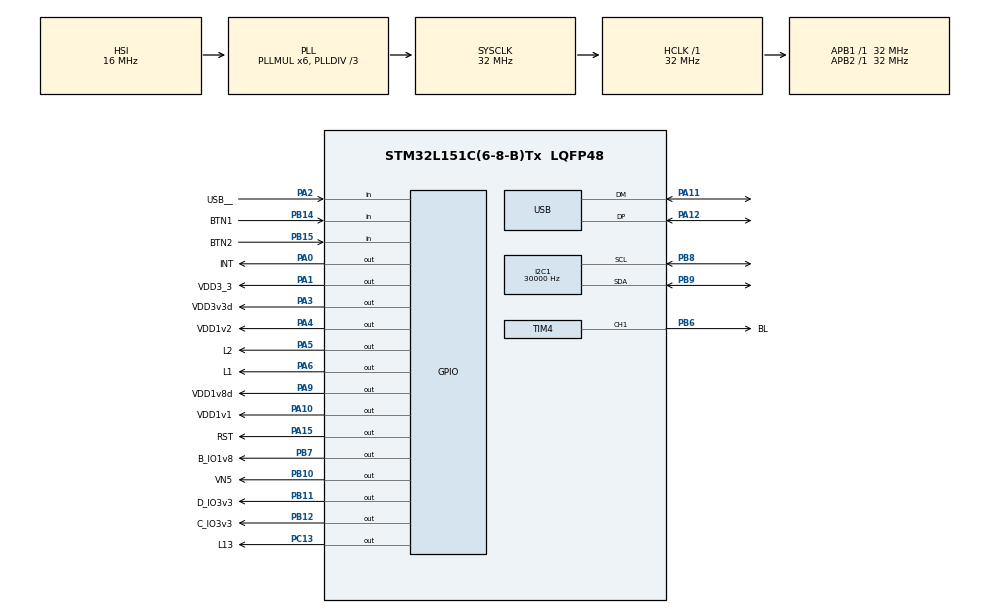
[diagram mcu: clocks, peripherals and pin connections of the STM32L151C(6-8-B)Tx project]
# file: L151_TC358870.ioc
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ADC.Channel-10\#ChannelRegularConversion=ADC_CHANNEL_TEMPSENSOR
ADC.Channel-9\#ChannelRegularConversion=ADC_CHANNEL_VREFINT
ADC.NbrOfConversion=2
ADC.NbrOfConversionFlag=1
ADC.Rank-10\#ChannelRegularConversion=2
ADC.Rank-9\#ChannelRegularConversion=1
ADC.SamplingTime-10\#ChannelRegularConversion=ADC_SAMPLETIME_384CYCLES
ADC.SamplingTime-9\#ChannelRegularConversion=ADC_SAMPLETIME_384CYCLES
I2C1.ClockSpeed=30000
I2C1.I2C_Mode=I2C_Standard
Mcu.Family=STM32L1
Mcu.Name=STM32L151C(6-8-B)Tx
Mcu.Package=LQFP48
NVIC.PriorityGroup=NVIC_PRIORITYGROUP_4
NVIC.USB_LP_IRQn=true\:0\:0\:false\:false\:true\:false\:true\:true
PA0-WKUP1.GPIO_Label=INT
PA0-WKUP1.GPIO_ModeDefaultOutputPP=GPIO_MODE_OUTPUT_OD
PA0-WKUP1.GPIO_PuPd=GPIO_PULLUP
PA0-WKUP1.GPIO_Speed=GPIO_SPEED_FREQ_VERY_HIGH
PA0-WKUP1.PinState=GPIO_PIN_SET
PA0-WKUP1.Signal=GPIO_Output
PA1.GPIO_Label=VDD3_3
PA1.GPIO_Speed=GPIO_SPEED_FREQ_VERY_HIGH
PA1.PinState=GPIO_PIN_RESET
PA1.Signal=GPIO_Output
PA10.GPIO_Label=VDD1v1
PA10.GPIO_Speed=GPIO_SPEED_FREQ_VERY_HIGH
PA10.PinState=GPIO_PIN_RESET
PA10.Signal=GPIO_Output
PA11.Mode=Device
PA11.Signal=USB_DM
PA12.Mode=Device
PA12.Signal=USB_DP
PA13.Mode=Serial_Wire
PA13.Signal=SYS_JTMS-SWDIO
PA14.Mode=Serial_Wire
PA14.Signal=SYS_JTCK-SWCLK
PA15.GPIO_Label=RST
PA15.GPIO_Speed=GPIO_SPEED_FREQ_VERY_HIGH
PA15.PinState=GPIO_PIN_RESET
PA15.Signal=GPIO_Output
PA2.GPIO_Label=USB__
PA2.Signal=GPIO_Input
PA3.GPIO_Label=VDD3v3d
PA3.GPIO_Speed=GPIO_SPEED_FREQ_VERY_HIGH
PA3.PinState=GPIO_PIN_SET
PA3.Signal=GPIO_Output
PA4.GPIO_Label=VDD1v2
PA4.GPIO_Speed=GPIO_SPEED_FREQ_VERY_HIGH
PA4.PinState=GPIO_PIN_RESET
PA4.Signal=GPIO_Output
PA5.GPIO_Label=L2
PA5.GPIO_Speed=GPIO_SPEED_FREQ_VERY_HIGH
PA5.Signal=GPIO_Output
PA6.GPIO_Label=L1
PA6.GPIO_Speed=GPIO_SPEED_FREQ_VERY_HIGH
PA6.Signal=GPIO_Output
PA9.GPIO_Label=VDD1v8d
PA9.GPIO_Speed=GPIO_SPEED_FREQ_VERY_HIGH
PA9.Signal=GPIO_Output
PB10.GPIO_Label=VN5
PB10.GPIO_Speed=GPIO_SPEED_FREQ_VERY_HIGH
PB10.PinState=GPIO_PIN_RESET
PB10.Signal=GPIO_Output
PB11.GPIO_Label=D_IO3v3
PB11.GPIO_Speed=GPIO_SPEED_FREQ_VERY_HIGH
PB11.PinState=GPIO_PIN_RESET
PB11.Signal=GPIO_Output
PB12.GPIO_Label=C_IO3v3
PB12.GPIO_Speed=GPIO_SPEED_FREQ_VERY_HIGH
PB12.PinState=GPIO_PIN_RESET
PB12.Signal=GPIO_Output
PB14.GPIO_Label=BTN1
PB14.Signal=GPIO_Input
PB15.GPIO_Label=BTN2
PB15.Signal=GPIO_Input
PB6.GPIO_Label=BL
PB6.Signal=S_TIM4_CH1
PB7.GPIO_Label=B_IO1v8
PB7.GPIO_Speed=GPIO_SPEED_FREQ_VERY_HIGH
PB7.PinState=GPIO_PIN_RESET
PB7.Signal=GPIO_Output
PB8.Mode=I2C
PB8.Signal=I2C1_SCL
PB9.Mode=I2C
PB9.Signal=I2C1_SDA
PC13-WKUP2.GPIO_Label=L13
PC13-WKUP2.Signal=GPIO_Output
ProjectManager.HeapSize=0x200
ProjectManager.StackSize=0x400
ProjectManager.TargetToolchain=STM32CubeIDE
RCC.48MHZClocksFreq_Value=48000000
RCC.AHBFreq_Value=32000000
RCC.APB1Freq_Value=32000000
RCC.APB1TimFreq_Value=32000000
RCC.APB2Freq_Value=32000000
RCC.APB2TimFreq_Value=32000000
RCC.HCLKFreq_Value=32000000
RCC.HSE_VALUE=12000000
RCC.HSI_VALUE=16000000
RCC.LSE_VALUE=32768
RCC.MSI_VALUE=2097000
RCC.PLLDIV=RCC_PLL_DIV3
RCC.PLLMUL=RCC_PLL_MUL6
RCC.PLLSource=RCC_PLLSOURCE_HSI
RCC.PLLSourceVirtualString=RCC_PLLSOURCE_HSI
RCC.SYSCLKFreq_VALUE=32000000
RCC.SYSCLKSource=RCC_SYSCLKSOURCE_PLLCLK
RCC.VCOOutputFreq_Value=96000000
SH.S_TIM4_CH1.0=TIM4_CH1,PWM Generation1 CH1
TIM4.Channel-PWM\ Generation1\ CH1=TIM_CHANNEL_1
TIM4.Period=100
TIM4.Prescaler=3
TIM4.Pulse-PWM\ Generation1\ CH1=50
USB_DEVICE.CLASS_NAME_FS=CDC
USB_DEVICE.VirtualMode=Cdc
USB_DEVICE.VirtualModeFS=Cdc_FS
VP_ADC_TempSens_Input.Mode=IN-TempSens
VP_ADC_Vref_Input.Mode=IN-Vrefint
VP_USB_DEVICE_VS_USB_DEVICE_CDC_FS.Mode=CDC_FS
board=custom

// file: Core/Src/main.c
/* USER CODE BEGIN Header */
/**
  ******************************************************************************
  * @file           : main.c
  * @brief          : Main program body
  ******************************************************************************
  * @attention
  *
  * Copyright (c) 2024 STMicroelectronics.
  * All rights reserved.
  *
  * This software is licensed under terms that can be found in the LICENSE file
  * in the root directory of this software component.
  * If no LICENSE file comes with this software, it is provided AS-IS.
  *
  ******************************************************************************
  */
/* USER CODE END Header */
#include "main.h"
#include "adc.h"
#include "i2c.h"
#include "tim.h"
#include "usb_device.h"
#include "gpio.h"

/* USER CODE BEGIN Includes */
#include "kernel.h"
/* USER CODE END Includes */

void SystemClock_Config(void);

int main(void)
{

  /* MCU Configuration--------------------------------------------------------*/

  /* Reset of all peripherals, Initializes the Flash interface and the Systick. */
  HAL_Init();

  /* Configure the system clock */
  SystemClock_Config();

  /* Initialize all configured peripherals */
  MX_GPIO_Init();
  MX_ADC_Init();
//  MX_USB_DEVICE_Init();
  MX_I2C1_Init();
  MX_TIM4_Init();

  /* Infinite loop */
  /* USER CODE BEGIN WHILE */
  while (1)
  {
	  kernel_main();
    /* USER CODE END WHILE */

  }
}

void SystemClock_Config(void)
{
  RCC_OscInitTypeDef RCC_OscInitStruct = {0};
  RCC_ClkInitTypeDef RCC_ClkInitStruct = {0};

  /** Configure the main internal regulator output voltage
  */
  __HAL_PWR_VOLTAGESCALING_CONFIG(PWR_REGULATOR_VOLTAGE_SCALE1);

  /** Initializes the RCC Oscillators according to the specified parameters
  * in the RCC_OscInitTypeDef structure.
  */
  RCC_OscInitStruct.OscillatorType = RCC_OSCILLATORTYPE_HSI;
  RCC_OscInitStruct.HSIState = RCC_HSI_ON;
  RCC_OscInitStruct.HSICalibrationValue = RCC_HSICALIBRATION_DEFAULT;
  RCC_OscInitStruct.PLL.PLLState = RCC_PLL_ON;
  RCC_OscInitStruct.PLL.PLLSource = RCC_PLLSOURCE_HSI;
  RCC_OscInitStruct.PLL.PLLMUL = RCC_PLL_MUL6;
  RCC_OscInitStruct.PLL.PLLDIV = RCC_PLL_DIV3;
  if (HAL_RCC_OscConfig(&RCC_OscInitStruct) != HAL_OK)
  {
    Error_Handler();
  }

  /** Initializes the CPU, AHB and APB buses clocks
  */
  RCC_ClkInitStruct.ClockType = RCC_CLOCKTYPE_HCLK|RCC_CLOCKTYPE_SYSCLK
                              |RCC_CLOCKTYPE_PCLK1|RCC_CLOCKTYPE_PCLK2;
  RCC_ClkInitStruct.SYSCLKSource = RCC_SYSCLKSOURCE_PLLCLK;
  RCC_ClkInitStruct.AHBCLKDivider = RCC_SYSCLK_DIV1;
  RCC_ClkInitStruct.APB1CLKDivider = RCC_HCLK_DIV1;
  RCC_ClkInitStruct.APB2CLKDivider = RCC_HCLK_DIV1;

  if (HAL_RCC_ClockConfig(&RCC_ClkInitStruct, FLASH_LATENCY_1) != HAL_OK)
  {
    Error_Handler();
  }
}

void Error_Handler(void)
{
  /* USER CODE BEGIN Error_Handler_Debug */
  /* User can add his own implementation to report the HAL error return state */
  __disable_irq();
  while (1)
  {
	  HAL_GPIO_WritePin(L13_GPIO_Port, L13_Pin, 1);
	  HAL_Delay(300);
	  HAL_GPIO_WritePin(L13_GPIO_Port, L13_Pin, 0);
	  HAL_Delay(300);
  }
  /* USER CODE END Error_Handler_Debug */
}
